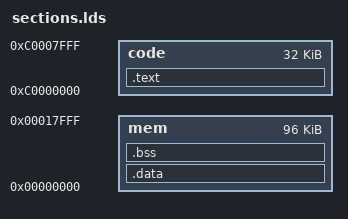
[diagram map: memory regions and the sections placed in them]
/*
This is free and unencumbered software released into the public domain.

Anyone is free to copy, modify, publish, use, compile, sell, or
distribute this software, either in source code form or as a compiled
binary, for any purpose, commercial or non-commercial, and by any
means.
*/

MEMORY {
	/* the memory in the testbench is 128k in size;
	 * set LENGTH=96k and leave at least 32k for stack */
	mem : ORIGIN = 0x00000000, LENGTH = 0x00018000
	code : ORIGIN = 0xc0000000, LENGTH = 0x00008000
}

SECTIONS {
    .text :
    {
        . = ALIGN(4);
        *(.text)
        *(.text*)
        *(.rodata)
        *(.rodata*)
        *(.srodata)
        *(.srodata*)
        . = ALIGN(4);
        _etext = .;
        _sidata = _etext;
    } >code
    .data : AT ( _sidata )
    {
        . = ALIGN(4);
        _sdata = .;
        _ram_start = .;
        . = ALIGN(4);
        *(.data)
        *(.data*)
        *(.sdata)
        *(.sdata*)
        . = ALIGN(4);
        _edata = .;
    } >mem
    .bss :
    {
        . = ALIGN(4);
        _sbss = .;
        *(.bss)
        *(.bss*)
        *(.sbss)
        *(.sbss*)
        *(COMMON)
        . = ALIGN(4);
        _ebss = .;
    } >mem
}
